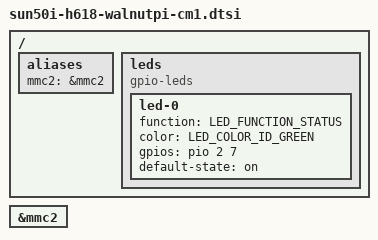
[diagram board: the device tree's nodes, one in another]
// SPDX-License-Identifier: (GPL-2.0+ OR MIT)
/*
 * Walnut Pi CM1 compute module: Walnut Pi 1 family core with eMMC
 * populated (mmc2) and the status LED on PC7.
 */

#include "sun50i-h618-walnutpi.dtsi"

/ {
	aliases {
		mmc2 = &mmc2;
	};

	leds {
		compatible = "gpio-leds";

		led-0 {
			function = LED_FUNCTION_STATUS;
			color = <LED_COLOR_ID_GREEN>;
			gpios = <&pio 2 7 GPIO_ACTIVE_HIGH>; /* PC7 */
			default-state = "on";
		};
	};
};

&mmc2 {
	status = "okay";
};
